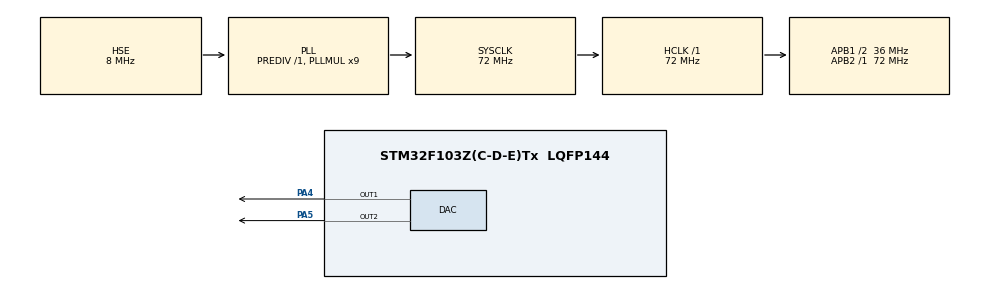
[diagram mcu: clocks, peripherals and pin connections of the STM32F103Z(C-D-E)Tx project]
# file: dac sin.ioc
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DAC.DAC_Trigger=DAC_TRIGGER_T2_TRGO
DAC.DAC_Trigger2=DAC_TRIGGER_T4_TRGO
DAC.TriangleAmplitude2=DAC_TRIANGLEAMPLITUDE_4095
DAC.WaveGeneration2=TriangleWaveGeneration
Dma.DAC_CH1.0.Direction=DMA_MEMORY_TO_PERIPH
Dma.DAC_CH1.0.Instance=DMA2_Channel3
Dma.DAC_CH1.0.MemDataAlignment=DMA_MDATAALIGN_HALFWORD
Dma.DAC_CH1.0.MemInc=DMA_MINC_ENABLE
Dma.DAC_CH1.0.Mode=DMA_CIRCULAR
Dma.DAC_CH1.0.PeriphDataAlignment=DMA_PDATAALIGN_HALFWORD
Dma.DAC_CH1.0.PeriphInc=DMA_PINC_DISABLE
Dma.DAC_CH1.0.Priority=DMA_PRIORITY_LOW
Dma.Request0=DAC_CH1
Mcu.Family=STM32F1
Mcu.Name=STM32F103Z(C-D-E)Tx
Mcu.Package=LQFP144
NVIC.DMA2_Channel3_IRQn=true\:0\:0\:false\:false\:true\:false\:true
NVIC.PriorityGroup=NVIC_PRIORITYGROUP_4
OSC_IN.Mode=HSE-External-Oscillator
OSC_IN.Signal=RCC_OSC_IN
OSC_OUT.Mode=HSE-External-Oscillator
OSC_OUT.Signal=RCC_OSC_OUT
PA13.Mode=Serial_Wire
PA13.Signal=SYS_JTMS-SWDIO
PA14.Mode=Serial_Wire
PA14.Signal=SYS_JTCK-SWCLK
PA4.Signal=COMP_DAC1_group
PA5.Signal=COMP_DAC2_group
ProjectManager.HeapSize=0x200
ProjectManager.StackSize=0x400
ProjectManager.TargetToolchain=MDK-ARM V5.32
RCC.AHBFreq_Value=72000000
RCC.APB1CLKDivider=RCC_HCLK_DIV2
RCC.APB1Freq_Value=36000000
RCC.APB1TimFreq_Value=72000000
RCC.APB2Freq_Value=72000000
RCC.APB2TimFreq_Value=72000000
RCC.HCLKFreq_Value=72000000
RCC.PLLMUL=RCC_PLL_MUL9
RCC.PLLSourceVirtual=RCC_PLLSOURCE_HSE
RCC.SYSCLKFreq_VALUE=72000000
RCC.SYSCLKSource=RCC_SYSCLKSOURCE_PLLCLK
RCC.USBFreq_Value=72000000
SH.COMP_DAC1_group.0=DAC_OUT1,DAC_OUT1
SH.COMP_DAC2_group.0=DAC_OUT2,DAC_OUT2
TIM2.AutoReloadPreload=TIM_AUTORELOAD_PRELOAD_ENABLE
TIM2.Period=500-1
TIM2.Prescaler=72-1
TIM2.TIM_MasterOutputTrigger=TIM_TRGO_UPDATE
TIM4.AutoReloadPreload=TIM_AUTORELOAD_PRELOAD_DISABLE
TIM4.Period=0xa
TIM4.Prescaler=0x2
TIM4.TIM_MasterOutputTrigger=TIM_TRGO_UPDATE
VP_TIM2_VS_ClockSourceINT.Mode=Internal
VP_TIM4_VS_ClockSourceINT.Mode=Internal
board=custom

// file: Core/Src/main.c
/* USER CODE BEGIN Header */
/**
  ******************************************************************************
  * @file           : main.c
  * @brief          : Main program body
  ******************************************************************************
  * @attention
  *
  * Copyright (c) 2023 STMicroelectronics.
  * All rights reserved.
  *
  * This software is licensed under terms that can be found in the LICENSE file
  * in the root directory of this software component.
  * If no LICENSE file comes with this software, it is provided AS-IS.
  *
  ******************************************************************************
  */
/* USER CODE END Header */
#include "main.h"
#include "dac.h"
#include "dma.h"
#include "tim.h"
#include "gpio.h"

/* USER CODE BEGIN Includes */
/* Private define ------------------------------------------------------------*/
#include "math.h"
#define POINTS 2048
uint16_t SineWaveTable[POINTS] = {0};

/* USER CODE END Includes */

void SystemClock_Config(void);

/* USER CODE BEGIN 0 */
/**
 * 生成正弦波数据点函数
 * @param NPoints       一个周期内的点数
 * @param VMaxRange     输出的电压最大值，取值范围0~3.3V
 * @param SineWaveTable 存放生成的数据点
 */
void SineWaveGen(uint32_t NPoints, float VMaxRange, uint16_t* SineWaveTable)
{
#ifndef PI
#define PI 3.14159265358979323846
#endif

	int    i       = 0;
	double radian  = 0;  // 弧度
	double setup   = 0;  // 弧度和弧度之间的大小
	double voltage = 0;  // 输出电压

	setup = (2 * PI) / NPoints;  // 两点之间的间距

	while (i < NPoints)
	{
		voltage = VMaxRange / 2.0 * (sin(radian) + 1.0);              // 计算电压
		SineWaveTable[i] = (uint16_t)(voltage * 4096 / 3.3);          // 电压转为DAC数值
		radian += setup;                                              // 下一个点的弧度
		i++;
	}
}

/* USER CODE END 0 */

int main(void)
{

  /* MCU Configuration--------------------------------------------------------*/

  /* Reset of all peripherals, Initializes the Flash interface and the Systick. */
  HAL_Init();

  /* Configure the system clock */
  SystemClock_Config();

  /* Initialize all configured peripherals */
  MX_GPIO_Init();
  MX_DMA_Init();
  MX_DAC_Init();
  MX_TIM2_Init();
  MX_TIM4_Init();
  /* USER CODE BEGIN 2 */
  /* USER CODE BEGIN 2 */
	/* 在main 函数里面初始化 */

	 HAL_TIM_Base_Start(&htim4);
   HAL_DAC_Start(&hdac, DAC_CHANNEL_2);

 		/* 输出正弦波 */
		SineWaveGen(POINTS,3,(uint16_t *)SineWaveTable);
	 HAL_TIM_Base_Start(&htim2);			//开启定时器
	 HAL_DAC_Start_DMA(&hdac, DAC_CHANNEL_1, (uint32_t *)SineWaveTable, POINTS, DAC_ALIGN_12B_R);  //产生正弦波

  /* USER CODE END 2 */

  /* Infinite loop */
  while (1)
  {

  }
}

void SystemClock_Config(void)
{
  RCC_OscInitTypeDef RCC_OscInitStruct = {0};
  RCC_ClkInitTypeDef RCC_ClkInitStruct = {0};

  /** Initializes the RCC Oscillators according to the specified parameters
  * in the RCC_OscInitTypeDef structure.
  */
  RCC_OscInitStruct.OscillatorType = RCC_OSCILLATORTYPE_HSE;
  RCC_OscInitStruct.HSEState = RCC_HSE_ON;
  RCC_OscInitStruct.HSEPredivValue = RCC_HSE_PREDIV_DIV1;
  RCC_OscInitStruct.HSIState = RCC_HSI_ON;
  RCC_OscInitStruct.PLL.PLLState = RCC_PLL_ON;
  RCC_OscInitStruct.PLL.PLLSource = RCC_PLLSOURCE_HSE;
  RCC_OscInitStruct.PLL.PLLMUL = RCC_PLL_MUL9;
  if (HAL_RCC_OscConfig(&RCC_OscInitStruct) != HAL_OK)
  {
    Error_Handler();
  }
  /** Initializes the CPU, AHB and APB buses clocks
  */
  RCC_ClkInitStruct.ClockType = RCC_CLOCKTYPE_HCLK|RCC_CLOCKTYPE_SYSCLK
                              |RCC_CLOCKTYPE_PCLK1|RCC_CLOCKTYPE_PCLK2;
  RCC_ClkInitStruct.SYSCLKSource = RCC_SYSCLKSOURCE_PLLCLK;
  RCC_ClkInitStruct.AHBCLKDivider = RCC_SYSCLK_DIV1;
  RCC_ClkInitStruct.APB1CLKDivider = RCC_HCLK_DIV2;
  RCC_ClkInitStruct.APB2CLKDivider = RCC_HCLK_DIV1;

  if (HAL_RCC_ClockConfig(&RCC_ClkInitStruct, FLASH_LATENCY_2) != HAL_OK)
  {
    Error_Handler();
  }
}

void Error_Handler(void)
{
  __disable_irq();
  while (1)
  {
  }
}
